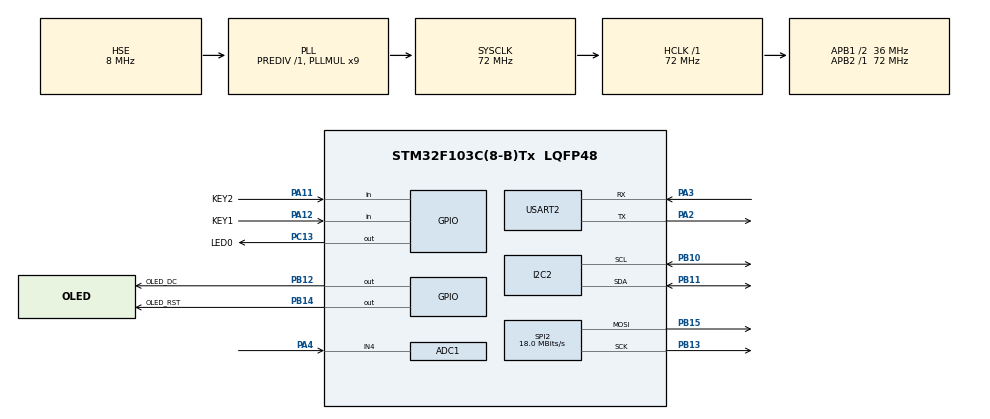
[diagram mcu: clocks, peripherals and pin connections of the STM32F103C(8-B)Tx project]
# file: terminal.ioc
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ADC1.Channel-0\#ChannelRegularConversion=ADC_CHANNEL_4
ADC1.NbrOfConversionFlag=1
ADC1.Rank-0\#ChannelRegularConversion=1
ADC1.SamplingTime-0\#ChannelRegularConversion=ADC_SAMPLETIME_1CYCLE_5
ADC1.master=1
Dma.ADC1.0.Direction=DMA_PERIPH_TO_MEMORY
Dma.ADC1.0.Instance=DMA1_Channel1
Dma.ADC1.0.MemDataAlignment=DMA_MDATAALIGN_HALFWORD
Dma.ADC1.0.MemInc=DMA_MINC_ENABLE
Dma.ADC1.0.Mode=DMA_NORMAL
Dma.ADC1.0.PeriphDataAlignment=DMA_PDATAALIGN_HALFWORD
Dma.ADC1.0.PeriphInc=DMA_PINC_DISABLE
Dma.ADC1.0.Priority=DMA_PRIORITY_LOW
Dma.Request0=ADC1
Dma.Request1=USART2_RX
Dma.USART2_RX.1.Direction=DMA_PERIPH_TO_MEMORY
Dma.USART2_RX.1.Instance=DMA1_Channel6
Dma.USART2_RX.1.MemDataAlignment=DMA_MDATAALIGN_BYTE
Dma.USART2_RX.1.MemInc=DMA_MINC_ENABLE
Dma.USART2_RX.1.Mode=DMA_NORMAL
Dma.USART2_RX.1.PeriphDataAlignment=DMA_PDATAALIGN_BYTE
Dma.USART2_RX.1.PeriphInc=DMA_PINC_DISABLE
Dma.USART2_RX.1.Priority=DMA_PRIORITY_LOW
I2C2.I2C_Mode=I2C_Fast
Mcu.Family=STM32F1
Mcu.Name=STM32F103C(8-B)Tx
Mcu.Package=LQFP48
NVIC.DMA1_Channel1_IRQn=true\:0\:0\:false\:false\:true\:false\:true\:true
NVIC.DMA1_Channel6_IRQn=true\:0\:0\:false\:false\:true\:false\:true\:true
NVIC.PriorityGroup=NVIC_PRIORITYGROUP_4
NVIC.TIM2_IRQn=true\:0\:0\:false\:false\:true\:true\:true\:true
NVIC.TIM3_IRQn=true\:0\:0\:false\:false\:true\:true\:true\:true
NVIC.TIM4_IRQn=true\:0\:0\:false\:false\:true\:true\:true\:true
NVIC.USART2_IRQn=true\:0\:0\:false\:false\:true\:true\:true\:true
PA11.GPIO_Label=KEY2
PA11.GPIO_PuPd=GPIO_PULLUP
PA11.Signal=GPIO_Input
PA12.GPIO_Label=KEY1
PA12.GPIO_PuPd=GPIO_PULLUP
PA12.Signal=GPIO_Input
PA13.Mode=Serial_Wire
PA13.Signal=SYS_JTMS-SWDIO
PA14.Mode=Serial_Wire
PA14.Signal=SYS_JTCK-SWCLK
PA2.Mode=Asynchronous
PA2.Signal=USART2_TX
PA3.Mode=Asynchronous
PA3.Signal=USART2_RX
PA4.Signal=ADCx_IN4
PB10.Mode=I2C
PB10.Signal=I2C2_SCL
PB11.Mode=I2C
PB11.Signal=I2C2_SDA
PB12.GPIO_Label=OLED_DC
PB12.GPIO_PuPd=GPIO_PULLUP
PB12.GPIO_Speed=GPIO_SPEED_FREQ_MEDIUM
PB12.PinState=GPIO_PIN_SET
PB12.Signal=GPIO_Output
PB13.Mode=TX_Only_Simplex_Unidirect_Master
PB13.Signal=SPI2_SCK
PB14.GPIO_Label=OLED_RST
PB14.GPIO_PuPd=GPIO_PULLUP
PB14.GPIO_Speed=GPIO_SPEED_FREQ_MEDIUM
PB14.PinState=GPIO_PIN_SET
PB14.Signal=GPIO_Output
PB15.Mode=TX_Only_Simplex_Unidirect_Master
PB15.Signal=SPI2_MOSI
PC13-TAMPER-RTC.GPIO_Label=LED0
PC13-TAMPER-RTC.Signal=GPIO_Output
PD0-OSC_IN.Mode=HSE-External-Oscillator
PD0-OSC_IN.Signal=RCC_OSC_IN
PD1-OSC_OUT.Mode=HSE-External-Oscillator
PD1-OSC_OUT.Signal=RCC_OSC_OUT
ProjectManager.HeapSize=0x200
ProjectManager.StackSize=0x400
ProjectManager.TargetToolchain=SW4STM32
RCC.ADCPresc=RCC_ADCPCLK2_DIV6
RCC.AHBFreq_Value=72000000
RCC.APB1CLKDivider=RCC_HCLK_DIV2
RCC.APB1Freq_Value=36000000
RCC.APB1TimFreq_Value=72000000
RCC.APB2Freq_Value=72000000
RCC.APB2TimFreq_Value=72000000
RCC.HCLKFreq_Value=72000000
RCC.PLLMUL=RCC_PLL_MUL9
RCC.PLLSourceVirtual=RCC_PLLSOURCE_HSE
RCC.SYSCLKFreq_VALUE=72000000
RCC.SYSCLKSource=RCC_SYSCLKSOURCE_PLLCLK
RCC.USBFreq_Value=48000000
RCC.USBPrescaler=RCC_USBCLKSOURCE_PLL_DIV1_5
SH.ADCx_IN4.0=ADC1_IN4,IN4
SPI2.BaudRatePrescaler=SPI_BAUDRATEPRESCALER_2
SPI2.CalculateBaudRate=18.0 MBits/s
SPI2.Direction=SPI_DIRECTION_2LINES
SPI2.Mode=SPI_MODE_MASTER
SPI2.VirtualType=VM_MASTER
TIM2.Period=50000-1
TIM2.Prescaler=72-1
TIM3.Period=10000-1
TIM3.Prescaler=72-1
TIM4.Period=5000-1
TIM4.Prescaler=72-1
USART2.VirtualMode=VM_ASYNC
VP_TIM2_VS_ClockSourceINT.Mode=Internal
VP_TIM3_VS_ClockSourceINT.Mode=Internal
VP_TIM4_VS_ClockSourceINT.Mode=Internal
board=custom

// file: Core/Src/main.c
/* USER CODE BEGIN Header */
/**
  ******************************************************************************
  * @file           : main.c
  * @brief          : Main program body
  ******************************************************************************
  * @attention
  *
  * Copyright (c) 2023 STMicroelectronics.
  * All rights reserved.
  *
  * This software is licensed under terms that can be found in the LICENSE file
  * in the root directory of this software component.
  * If no LICENSE file comes with this software, it is provided AS-IS.
  *
  ******************************************************************************
  */
/* USER CODE END Header */
#include "main.h"
#include "adc.h"
#include "dma.h"
#include "i2c.h"
#include "spi.h"
#include "tim.h"
#include "usart.h"
#include "gpio.h"

/* USER CODE BEGIN Includes */
#include "common_inc.h"
/* USER CODE END Includes */

void SystemClock_Config(void);

int main(void)
{

  /* MCU Configuration--------------------------------------------------------*/

  /* Reset of all peripherals, Initializes the Flash interface and the Systick. */
  HAL_Init();

  /* Configure the system clock */
  SystemClock_Config();

  /* USER CODE BEGIN SysInit */
    MX_DMA_Init();
  /* USER CODE END SysInit */

  /* Initialize all configured peripherals */
  MX_GPIO_Init();
  MX_I2C2_Init();
  MX_DMA_Init();
  MX_USART2_UART_Init();
  MX_ADC1_Init();
  MX_SPI2_Init();
  MX_TIM3_Init();
  MX_TIM4_Init();
  MX_TIM2_Init();
  /* USER CODE BEGIN 2 */

    Main();

  /* USER CODE END 2 */

  /* Infinite loop */
  while (1)
  {

  }
}

void SystemClock_Config(void)
{
  RCC_OscInitTypeDef RCC_OscInitStruct = {0};
  RCC_ClkInitTypeDef RCC_ClkInitStruct = {0};
  RCC_PeriphCLKInitTypeDef PeriphClkInit = {0};

  /** Initializes the RCC Oscillators according to the specified parameters
  * in the RCC_OscInitTypeDef structure.
  */
  RCC_OscInitStruct.OscillatorType = RCC_OSCILLATORTYPE_HSE;
  RCC_OscInitStruct.HSEState = RCC_HSE_ON;
  RCC_OscInitStruct.HSEPredivValue = RCC_HSE_PREDIV_DIV1;
  RCC_OscInitStruct.HSIState = RCC_HSI_ON;
  RCC_OscInitStruct.PLL.PLLState = RCC_PLL_ON;
  RCC_OscInitStruct.PLL.PLLSource = RCC_PLLSOURCE_HSE;
  RCC_OscInitStruct.PLL.PLLMUL = RCC_PLL_MUL9;
  if (HAL_RCC_OscConfig(&RCC_OscInitStruct) != HAL_OK)
  {
    Error_Handler();
  }

  /** Initializes the CPU, AHB and APB buses clocks
  */
  RCC_ClkInitStruct.ClockType = RCC_CLOCKTYPE_HCLK|RCC_CLOCKTYPE_SYSCLK
                              |RCC_CLOCKTYPE_PCLK1|RCC_CLOCKTYPE_PCLK2;
  RCC_ClkInitStruct.SYSCLKSource = RCC_SYSCLKSOURCE_PLLCLK;
  RCC_ClkInitStruct.AHBCLKDivider = RCC_SYSCLK_DIV1;
  RCC_ClkInitStruct.APB1CLKDivider = RCC_HCLK_DIV2;
  RCC_ClkInitStruct.APB2CLKDivider = RCC_HCLK_DIV1;

  if (HAL_RCC_ClockConfig(&RCC_ClkInitStruct, FLASH_LATENCY_2) != HAL_OK)
  {
    Error_Handler();
  }
  PeriphClkInit.PeriphClockSelection = RCC_PERIPHCLK_ADC;
  PeriphClkInit.AdcClockSelection = RCC_ADCPCLK2_DIV6;
  if (HAL_RCCEx_PeriphCLKConfig(&PeriphClkInit) != HAL_OK)
  {
    Error_Handler();
  }
}

void Error_Handler(void)
{
  __disable_irq();
  while (1)
  {
  }
}
